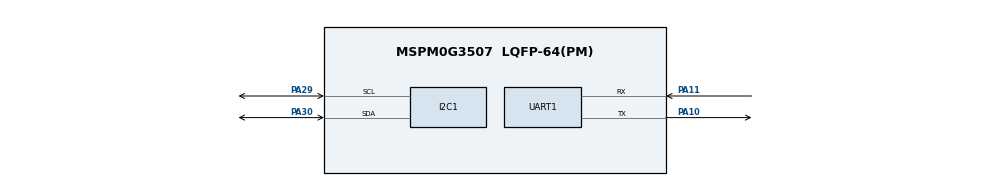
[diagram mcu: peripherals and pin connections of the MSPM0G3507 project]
/**
 * These arguments were used when this file was generated. They will be automatically applied on subsequent loads
 * via the GUI or CLI. Run CLI with '--help' for additional information on how to override these arguments.
 * @cliArgs --device "MSPM0G350X" --part "Default" --package "LQFP-64(PM)" --product "mspm0_sdk@2.10.00.04"
 * @v2CliArgs --device "MSPM0G3507" --package "LQFP-64(PM)" --product "mspm0_sdk@2.10.00.04"
 * @versions {"tool":"1.26.2+4477"}
 */

/**
 * Import the modules used in this configuration.
 */
const GPIO   = scripting.addModule("/ti/driverlib/GPIO", {}, false);
const GPIO1  = GPIO.addInstance();
const I2C    = scripting.addModule("/ti/driverlib/I2C", {}, false);
const I2C1   = I2C.addInstance();
const SYSCTL = scripting.addModule("/ti/driverlib/SYSCTL");
const UART   = scripting.addModule("/ti/driverlib/UART", {}, false);
const UART1  = UART.addInstance();

/**
 * Write custom configuration values to the imported modules.
 */
GPIO1.$name                         = "GPIO_VL53L1x";
GPIO1.associatedPins.create(2);
GPIO1.associatedPins[0].$name       = "SHUT";
GPIO1.associatedPins[1].direction   = "INPUT";
GPIO1.associatedPins[1].interruptEn = true;
GPIO1.associatedPins[1].$name       = "INT";
GPIO1.associatedPins[1].polarity    = "FALL";

const Board = scripting.addModule("/ti/driverlib/Board", {}, false);

I2C1.$name                             = "I2C_VL53L1x";
I2C1.basicEnableController             = true;
I2C1.basicControllerStandardBusSpeed   = "Fast";
I2C1.peripheral.$assign                = "I2C1";
I2C1.peripheral.sdaPin.$assign         = "PA30";
I2C1.peripheral.sclPin.$assign         = "PA29";
I2C1.sdaPinConfig.$name                = "ti_driverlib_gpio_GPIOPinGeneric0";
I2C1.sdaPinConfig.hideOutputInversion  = scripting.forceWrite(false);
I2C1.sdaPinConfig.onlyInternalResistor = scripting.forceWrite(false);
I2C1.sdaPinConfig.passedPeripheralType = scripting.forceWrite("Digital");
I2C1.sclPinConfig.$name                = "ti_driverlib_gpio_GPIOPinGeneric1";
I2C1.sclPinConfig.hideOutputInversion  = scripting.forceWrite(false);
I2C1.sclPinConfig.onlyInternalResistor = scripting.forceWrite(false);
I2C1.sclPinConfig.passedPeripheralType = scripting.forceWrite("Digital");

SYSCTL.forceDefaultClkConfig = true;

UART1.$name                    = "UART_0";
UART1.targetBaudRate           = 115200;
UART1.peripheral.$assign       = "UART0";
UART1.peripheral.rxPin.$assign = "PA11";
UART1.peripheral.txPin.$assign = "PA10";
UART1.txPinConfig.$name        = "ti_driverlib_gpio_GPIOPinGeneric2";
UART1.rxPinConfig.$name        = "ti_driverlib_gpio_GPIOPinGeneric3";

/**
 * Pinmux solution for unlocked pins/peripherals. This ensures that minor changes to the automatic solver in a future
 * version of the tool will not impact the pinmux you originally saw.  These lines can be completely deleted in order to
 * re-solve from scratch.
 */
GPIO1.associatedPins[0].pin.$suggestSolution = "PB13";
GPIO1.associatedPins[1].pin.$suggestSolution = "PB14";
Board.peripheral.$suggestSolution            = "DEBUGSS";
Board.peripheral.swclkPin.$suggestSolution   = "PA20";
Board.peripheral.swdioPin.$suggestSolution   = "PA19";
SYSCTL.peripheral.$suggestSolution           = "SYSCTL";
